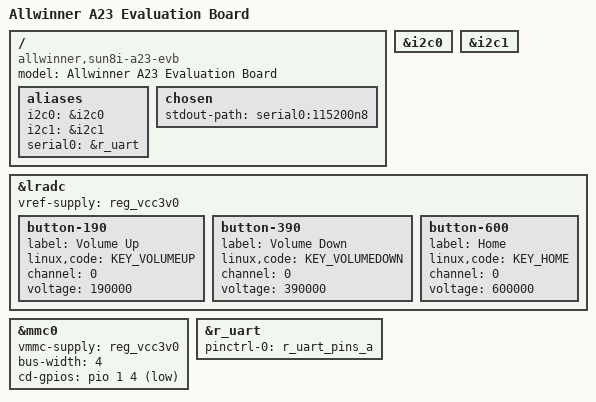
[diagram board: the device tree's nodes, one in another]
/dts-v1/;
#include "sun8i-a23.dtsi"
#include "sunxi-common-regulators.dtsi"
#include <dt-bindings/gpio/gpio.h>
#include <dt-bindings/input/input.h>
/ {
	model = "Allwinner A23 Evaluation Board";
	compatible = "allwinner,sun8i-a23-evb", "allwinner,sun8i-a23";
	aliases {
		i2c0 = &i2c0;
		i2c1 = &i2c1;
		serial0 = &r_uart;
	};
	chosen {
		stdout-path = "serial0:115200n8";
	};
};
&i2c0 {
	status = "okay";
};
&i2c1 {
	status = "okay";
};
&lradc {
	vref-supply = <&reg_vcc3v0>;
	status = "okay";
	button-190 {
		label = "Volume Up";
		linux,code = <KEY_VOLUMEUP>;
		channel = <0>;
		voltage = <190000>;
	};
	button-390 {
		label = "Volume Down";
		linux,code = <KEY_VOLUMEDOWN>;
		channel = <0>;
		voltage = <390000>;
	};
	button-600 {
		label = "Home";
		linux,code = <KEY_HOME>;
		channel = <0>;
		voltage = <600000>;
	};
};
&mmc0 {
	vmmc-supply = <&reg_vcc3v0>;
	bus-width = <4>;
	cd-gpios = <&pio 1 4 GPIO_ACTIVE_LOW>;  
	status = "okay";
};
&r_uart {
	pinctrl-names = "default";
	pinctrl-0 = <&r_uart_pins_a>;
	status = "okay";
};
